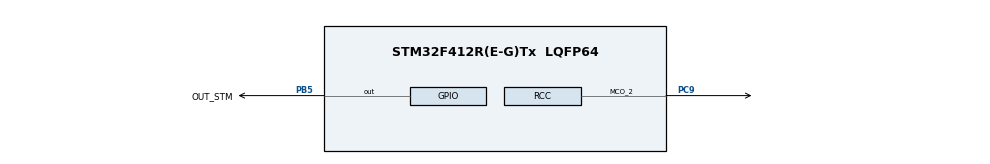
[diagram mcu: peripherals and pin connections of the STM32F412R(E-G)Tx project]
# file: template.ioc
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Mcu.Family=STM32F4
Mcu.Name=STM32F412R(E-G)Tx
Mcu.Package=LQFP64
NVIC.PriorityGroup=NVIC_PRIORITYGROUP_4
PB5.GPIO_Label=OUT_STM
PB5.Signal=GPIO_Output
PC9.Mode=Clock-out-2
PC9.Signal=RCC_MCO_2
PH0\ -\ OSC_IN.Mode=HSE-External-Oscillator
PH0\ -\ OSC_IN.Signal=RCC_OSC_IN
PH1\ -\ OSC_OUT.Mode=HSE-External-Oscillator
PH1\ -\ OSC_OUT.Signal=RCC_OSC_OUT
ProjectManager.HeapSize=0x200
ProjectManager.StackSize=0x400
ProjectManager.TargetToolchain=CMake
RCC.CortexFreq_Value=16000000
RCC.HSE_VALUE=16000000
RCC.USBFreq_Value=96000000
RCC.VCOOutputFreq_Value=192000000
board=custom

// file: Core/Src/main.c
/* USER CODE BEGIN Header */
/**
  ******************************************************************************
  * @file           : main.c
  * @brief          : Main program body
  ******************************************************************************
  * @attention
  *
  * Copyright (c) 2026 STMicroelectronics.
  * All rights reserved.
  *
  * This software is licensed under terms that can be found in the LICENSE file
  * in the root directory of this software component.
  * If no LICENSE file comes with this software, it is provided AS-IS.
  *
  ******************************************************************************
  */
/* USER CODE END Header */
#include "main.h"
#include "gpio.h"
#include "stm32f4xx_hal.h"
#include "stm32f4xx_hal_gpio.h"

void SystemClock_Config(void);

int main(void)
{

  /* MCU Configuration--------------------------------------------------------*/

  /* Reset of all peripherals, Initializes the Flash interface and the Systick. */
  HAL_Init();

  /* Configure the system clock */
  SystemClock_Config();

  /* Initialize all configured peripherals */
  MX_GPIO_Init();

  /* Infinite loop */
  /* USER CODE BEGIN WHILE */
  while (1)
  {
    HAL_GPIO_TogglePin(OUT_STM_GPIO_Port, OUT_STM_Pin);
    HAL_Delay(100);
    /* USER CODE END WHILE */

  }
}

void SystemClock_Config(void)
{
  RCC_OscInitTypeDef RCC_OscInitStruct = {0};
  RCC_ClkInitTypeDef RCC_ClkInitStruct = {0};

  /** Configure the main internal regulator output voltage
  */
  __HAL_RCC_PWR_CLK_ENABLE();
  __HAL_PWR_VOLTAGESCALING_CONFIG(PWR_REGULATOR_VOLTAGE_SCALE1);

  /** Initializes the RCC Oscillators according to the specified parameters
  * in the RCC_OscInitTypeDef structure.
  */
  RCC_OscInitStruct.OscillatorType = RCC_OSCILLATORTYPE_HSI;
  RCC_OscInitStruct.HSIState = RCC_HSI_ON;
  RCC_OscInitStruct.HSICalibrationValue = RCC_HSICALIBRATION_DEFAULT;
  RCC_OscInitStruct.PLL.PLLState = RCC_PLL_NONE;
  if (HAL_RCC_OscConfig(&RCC_OscInitStruct) != HAL_OK)
  {
    Error_Handler();
  }

  /** Initializes the CPU, AHB and APB buses clocks
  */
  RCC_ClkInitStruct.ClockType = RCC_CLOCKTYPE_HCLK|RCC_CLOCKTYPE_SYSCLK
                              |RCC_CLOCKTYPE_PCLK1|RCC_CLOCKTYPE_PCLK2;
  RCC_ClkInitStruct.SYSCLKSource = RCC_SYSCLKSOURCE_HSI;
  RCC_ClkInitStruct.AHBCLKDivider = RCC_SYSCLK_DIV1;
  RCC_ClkInitStruct.APB1CLKDivider = RCC_HCLK_DIV1;
  RCC_ClkInitStruct.APB2CLKDivider = RCC_HCLK_DIV1;

  if (HAL_RCC_ClockConfig(&RCC_ClkInitStruct, FLASH_LATENCY_0) != HAL_OK)
  {
    Error_Handler();
  }
  HAL_RCC_MCOConfig(RCC_MCO2, RCC_MCO2SOURCE_SYSCLK, RCC_MCODIV_1);
}

void Error_Handler(void)
{
  __disable_irq();
  while (1)
  {
  }
}
